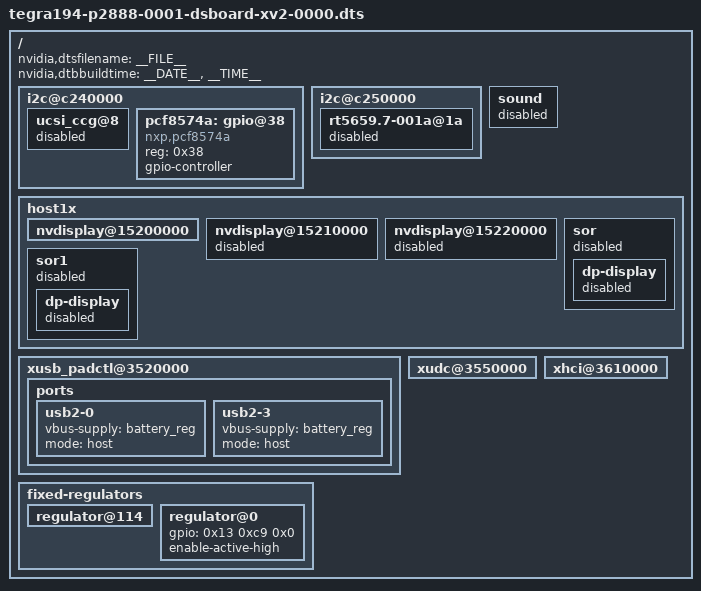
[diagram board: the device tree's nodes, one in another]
/*
 * Top level DTS file for CVM:P2888-0001 and CVB:DSBOARD-XV2.
 *
 * Copyright (c) 2020-2021, Mist Elektronik Biyomedikal Ltd. Şti.  All rights reserved.
 *
 * This program is free software; you can redistribute it and/or modify
 * it under the terms of the GNU General Public License as published by
 * the Free Software Foundation; version 2 of the License.
 *
 * This program is distributed in the hope that it will be useful, but WITHOUT
 * ANY WARRANTY; without even the implied warranty of MERCHANTABILITY or
 * FITNESS FOR A PARTICULAR PURPOSE.  See the GNU General Public License for
 * more details.
 */
#include "common/tegra194-p2888-0001-p2822-0000-common.dtsi"
#include "common/tegra194-p2822-0000-camera-dsboard-xv2-a00.dtsi"

/ {
	nvidia,dtsfilename = __FILE__;
	nvidia,dtbbuildtime = __DATE__, __TIME__;

	i2c@c240000 {
		ucsi_ccg@8 {
			status = "disabled";
		};
		pcf8574a: gpio@38 {
			compatible = "nxp,pcf8574a";
			reg = <0x38>;
			gpio-controller;
			#gpio-cells = <2>;
		};
	};

	i2c@c250000 {
		rt5659.7-001a@1a {
			status = "disabled";
		};
	};

	sound {
		status = "disabled";
	};

	host1x {

		nvdisplay@15200000 {
			/delete-property/  extcon-cables;
			/delete-property/  extcon-cable-names;
			/delete-property/  #extcon-cells;
		};

		nvdisplay@15210000 {
			/delete-property/  extcon-cables;
			/delete-property/  extcon-cable-names;
			/delete-property/  #extcon-cells;
			status="disabled";
		};

		nvdisplay@15220000 {
			/delete-property/  extcon-cables;
			/delete-property/  extcon-cable-names;
			/delete-property/  #extcon-cells;
			status="disabled";
		};

		sor {
			status = "disabled";
			/delete-property/  nvidia,typec-port;

			dp-display {
				status = "disabled";
			};
		};

		sor1 {
			status = "disabled";
			/delete-property/  nvidia,typec-port;

			dp-display {
				status = "disabled";
			};
		};

	};

	xusb_padctl@3520000 {

		ports {
			usb2-0 {
				status = "okay";
				vbus-supply = <&battery_reg>;
				mode = "host";
			};
			usb2-3 {
				status = "okay";
				vbus-supply = <&battery_reg>;
				mode = "host";
			};
		};
	};

	xudc@3550000 {
		/delete-property/  extcon-cables;
		/delete-property/  extcon-cable-names;
		/delete-property/  #extcon-cells;
	};

	xhci@3610000 {
		/delete-property/  extcon-cables;
		/delete-property/  extcon-cable-names;
		/delete-property/  #extcon-cells;
	};

	/delete-node/ usb_cd;
	
	fixed-regulators {
		regulator@114 {
			/delete-property/	gpio;
			/delete-property/	enable-active-high;
		};

		regulator@0 {
			/delete-property/	regulator-always-on;
			gpio = <0x13 0xc9 0x0>;
			enable-active-high;
		};
	};

};	


